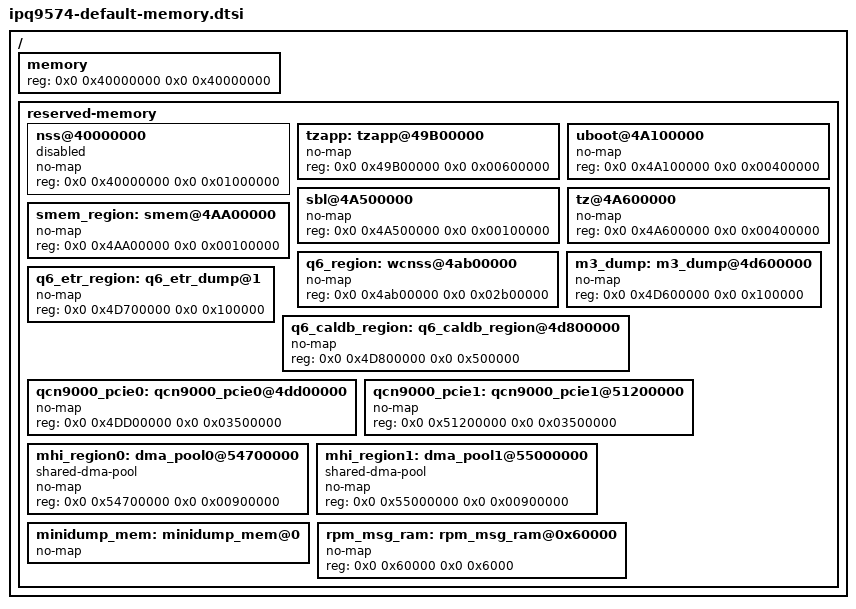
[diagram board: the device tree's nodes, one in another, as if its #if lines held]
// SPDX-License-Identifier: (GPL-2.0+ OR BSD-3-Clause)
/*
 * IPQ9574 Memory device tree source
 *
 * Copyright (c) 2021 The Linux Foundation. All rights reserved.
 * Copyright (c) 2024 Qualcomm Innovation Center, Inc. All rights reserved.
*/

/ {

	/*		  Default Profile
	 * +=========+==============+========================+
	 * |        |              |                         |
	 * | Region | Start Offset |          Size           |
	 * |        |              |                         |
	 * +--------+--------------+-------------------------+
	 * |        |              |                         |
	 * |        |              |                         |
	 * |        |              |                         |
	 * |        |              |                         |
	 * | Linux  |  0x41000000  |         139MB           |
	 * |        |              |                         |
	 * |        |              |                         |
	 * |        |              |                         |
	 * +--------+--------------+-------------------------+
	 * |        |              |                         |
	 * |        |              |                         |
	 * | TZ App |  0x49B00000  |           6MB           |
	 * |        |              |                         |
	 * |        |              |                         |
	 * +--------+--------------+-------------------------+
	 * |        |              |                         |
	 * | uboot  |  0x4A100000  |           4MB           |
	 * |        |              |                         |
	 * +--------+--------------+-------------------------+
	 * |  SBL   |  0x4A500000  |           1MB           |
	 * +--------+--------------+-------------------------+
	 * |        |              |                         |
	 * | TZ+HYP |  0x4A600000  |           4MB           |
	 * |        |              |                         |
	 * +--------+--------------+-------------------------+
	 * |  smem  |  0x4AA00000  |           1MB           |
	 * +--------+--------------+-------------------------+
	 * |        |              |                         |
	 * |        |              |                         |
	 * | WLAN   |              |                         |
	 * |   Q6   |  0x4AB00000  |          43MB           |
	 * |        |              |                         |
	 * |        |              |                         |
	 * +--------+--------------+-------------------------+
	 * | M3 Dump|  0x4D600000  |           1MB           |
	 * +--------+--------------+-------------------------+
	 * | WLAN   |              |                         |
	 * | Q6 ETR |  0x4D700000  |           1MB           |
	 * | Region |              |                         |
	 * +--------+--------------+-------------------------+
	 * | caldb  |  0x4D800000  |           5MB           |
	 * +--------+--------------+-------------------------+
	 * |        |              |                         |
	 * |  Pine0 |  0x4DD00000  |          53MB           |
	 * |        |              |                         |
	 * +--------+--------------+-------------------------+
	 * |        |              |                         |
	 * |  Pine1 |  0x51200000  |          53MB           |
	 * |        |              |                         |
	 * +--------+--------------+-------------------------+
	 * |        |              |                         |
	 * |  MHI0  |  0x54700000  |           9MB           |
	 * |        |              |                         |
	 * +--------+--------------+-------------------------+
	 * |        |              |                         |
	 * |  MHI1  |  0x55000000  |           9MB           |
	 * |        |              |                         |
	 * +=================================================+
	 * |                                                 |
	 * |                                                 |
	 * |                                                 |
	 * |            Rest of memory for Linux             |
	 * |                                                 |
	 * |                                                 |
	 * |                                                 |
	 * +=================================================+
	 */

	memory {
		device_type = "memory";
		reg = <0x0 0x40000000 0x0 0x40000000>;
	};

	reserved-memory {
		#address-cells = <2>;
		#size-cells = <2>;
		ranges;

		nss@40000000 {
			no-map;
			reg = <0x0 0x40000000 0x0 0x01000000>;
			status = "disabled";
		};

		tzapp:tzapp@49B00000 {  /* TZAPPS */
			no-map;
			reg = <0x0 0x49B00000 0x0 0x00600000>;
		};

		uboot@4A100000 {
			no-map;
			reg = <0x0 0x4A100000 0x0 0x00400000>;
		};

		sbl@4A500000 {
			no-map;
			reg = <0x0 0x4A500000 0x0 0x00100000>;
		};

		tz@4A600000 {
			no-map;
			reg = <0x0 0x4A600000 0x0 0x00400000>;
		};

		smem_region: smem@4AA00000 {
			no-map;
			reg = <0x0 0x4AA00000 0x0 0x00100000>;
		};

		q6_region: wcnss@4ab00000 {
			no-map;
			reg = <0x0 0x4ab00000 0x0 0x02b00000>;
		};

		m3_dump: m3_dump@4d600000 {
			no-map;
			reg = <0x0 0x4D600000 0x0 0x100000>;
		};

		q6_etr_region: q6_etr_dump@1 {
			no-map;
			reg = <0x0 0x4D700000 0x0 0x100000>;
		};

		q6_caldb_region:q6_caldb_region@4d800000 {
			no-map;
			reg = <0x0 0x4D800000 0x0 0x500000>;
		};

		qcn9000_pcie0: qcn9000_pcie0@4dd00000 {
			no-map;
			reg = <0x0 0x4DD00000 0x0 0x03500000>;
		};

		qcn9000_pcie1: qcn9000_pcie1@51200000 {
			no-map;
			reg = <0x0 0x51200000 0x0 0x03500000>;
		};

#if defined(__CNSS2__)
		mhi_region0: dma_pool0@54700000 {
			compatible = "shared-dma-pool";
			no-map;
			reg = <0x0 0x54700000 0x0 0x00900000>;
		};

		mhi_region1: dma_pool1@55000000 {
			compatible = "shared-dma-pool";
			no-map;
			reg = <0x0 0x55000000 0x0 0x00900000>;
		};
#endif
		minidump_mem: minidump_mem@0 {
			no-map;
		};

		rpm_msg_ram: rpm_msg_ram@0x60000 {
			no-map;
			reg = <0x0 0x60000 0x0 0x6000>;
		};
	};
};
